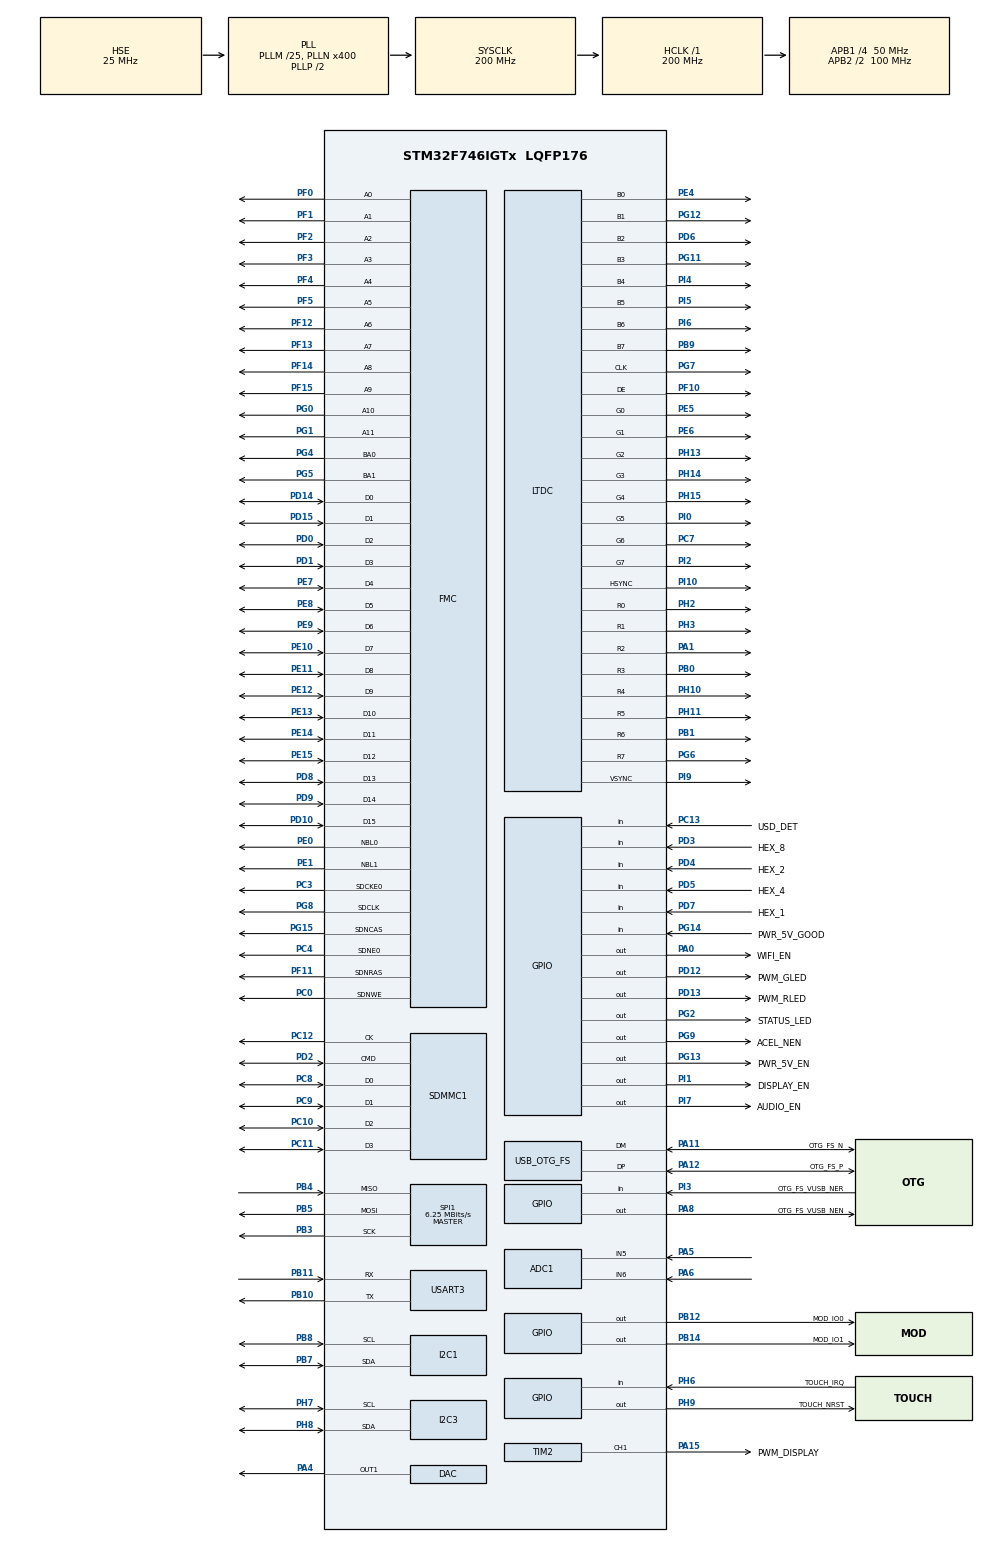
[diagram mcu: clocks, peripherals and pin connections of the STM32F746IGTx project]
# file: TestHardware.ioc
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ADC1.Channel-0\#ChannelRegularConversion=ADC_CHANNEL_5
ADC1.Channel-1\#ChannelRegularConversion=ADC_CHANNEL_6
ADC1.Channel-2\#ChannelRegularConversion=ADC_CHANNEL_TEMPSENSOR
ADC1.ClockPrescaler=ADC_CLOCK_SYNC_PCLK_DIV4
ADC1.ContinuousConvMode=DISABLE
ADC1.DMAContinuousRequests=ENABLE
ADC1.ExternalTrigConv=ADC_EXTERNALTRIGCONV_T1_TRGO
ADC1.NbrOfConversion=3
ADC1.NbrOfConversionFlag=1
ADC1.Rank-0\#ChannelRegularConversion=1
ADC1.Rank-1\#ChannelRegularConversion=2
ADC1.Rank-2\#ChannelRegularConversion=3
ADC1.SamplingTime-0\#ChannelRegularConversion=ADC_SAMPLETIME_28CYCLES
ADC1.SamplingTime-1\#ChannelRegularConversion=ADC_SAMPLETIME_15CYCLES
ADC1.SamplingTime-2\#ChannelRegularConversion=ADC_SAMPLETIME_480CYCLES
ADC1.ScanConvMode=ADC_SCAN_ENABLE
ADC1.master=1
CORTEX_M7.CPU_DCache=Enabled
CORTEX_M7.CPU_ICache=Enabled
DMA2D.ColorMode=DMA2D_OUTPUT_RGB888
Dma.ADC1.0.Direction=DMA_PERIPH_TO_MEMORY
Dma.ADC1.0.FIFOMode=DMA_FIFOMODE_DISABLE
Dma.ADC1.0.Instance=DMA2_Stream0
Dma.ADC1.0.MemDataAlignment=DMA_MDATAALIGN_HALFWORD
Dma.ADC1.0.MemInc=DMA_MINC_ENABLE
Dma.ADC1.0.Mode=DMA_CIRCULAR
Dma.ADC1.0.PeriphDataAlignment=DMA_PDATAALIGN_HALFWORD
Dma.ADC1.0.PeriphInc=DMA_PINC_DISABLE
Dma.ADC1.0.Priority=DMA_PRIORITY_LOW
Dma.Request0=ADC1
Dma.Request1=SDMMC1_RX
Dma.Request2=SDMMC1_TX
Dma.SDMMC1_RX.1.Direction=DMA_PERIPH_TO_MEMORY
Dma.SDMMC1_RX.1.FIFOMode=DMA_FIFOMODE_ENABLE
Dma.SDMMC1_RX.1.FIFOThreshold=DMA_FIFO_THRESHOLD_FULL
Dma.SDMMC1_RX.1.Instance=DMA2_Stream3
Dma.SDMMC1_RX.1.MemBurst=DMA_MBURST_INC4
Dma.SDMMC1_RX.1.MemDataAlignment=DMA_MDATAALIGN_WORD
Dma.SDMMC1_RX.1.MemInc=DMA_MINC_ENABLE
Dma.SDMMC1_RX.1.Mode=DMA_PFCTRL
Dma.SDMMC1_RX.1.PeriphBurst=DMA_PBURST_INC4
Dma.SDMMC1_RX.1.PeriphDataAlignment=DMA_PDATAALIGN_WORD
Dma.SDMMC1_RX.1.PeriphInc=DMA_PINC_DISABLE
Dma.SDMMC1_RX.1.Priority=DMA_PRIORITY_LOW
Dma.SDMMC1_TX.2.Direction=DMA_MEMORY_TO_PERIPH
Dma.SDMMC1_TX.2.FIFOMode=DMA_FIFOMODE_ENABLE
Dma.SDMMC1_TX.2.FIFOThreshold=DMA_FIFO_THRESHOLD_FULL
Dma.SDMMC1_TX.2.Instance=DMA2_Stream6
Dma.SDMMC1_TX.2.MemBurst=DMA_MBURST_INC4
Dma.SDMMC1_TX.2.MemDataAlignment=DMA_MDATAALIGN_WORD
Dma.SDMMC1_TX.2.MemInc=DMA_MINC_ENABLE
Dma.SDMMC1_TX.2.Mode=DMA_PFCTRL
Dma.SDMMC1_TX.2.PeriphBurst=DMA_PBURST_INC4
Dma.SDMMC1_TX.2.PeriphDataAlignment=DMA_PDATAALIGN_WORD
Dma.SDMMC1_TX.2.PeriphInc=DMA_PINC_DISABLE
Dma.SDMMC1_TX.2.Priority=DMA_PRIORITY_LOW
FATFS.BSP.number=1
FATFS.USE_DMA_CODE_SD=1
FATFS._USE_LFN=2
FATFS0.BSP.STBoard=false
FATFS0.BSP.api=Unknown
FATFS0.BSP.i2caddr=0
FATFS0.BSP.instance=PC13
FATFS0.BSP.ip=GPIO
FATFS0.BSP.mode=Input
FATFS0.BSP.name=Detect_SDIO
FATFS0.BSP.solution=PC13
FMC.CASLatency1=FMC_SDRAM_CAS_LATENCY_3
FMC.ExitSelfRefreshDelay1=7
FMC.LoadToActiveDelay1=2
FMC.RCDDelay1=2
FMC.RPDelay1=2
FMC.ReadBurst1=FMC_SDRAM_RBURST_ENABLE
FMC.RowCycleDelay1=7
FMC.SDClockPeriod1=FMC_SDRAM_CLOCK_PERIOD_2
FMC.SelfRefreshTime1=4
FMC.WriteRecoveryTime1=3
I2C1.Timing=0x00C0EAFF
I2C3.I2C_Fall_Time=100
I2C3.I2C_Rise_Time=100
I2C3.Timing=0xC0100F14
LTDC.ActiveH=272
LTDC.ActiveW=480
LTDC.Alpha_L0=255
LTDC.BlendingFactor1_L0=LTDC_BLENDING_FACTOR1_PAxCA
LTDC.BlendingFactor2_L0=LTDC_BLENDING_FACTOR2_PAxCA
LTDC.Blue_L0=0
LTDC.FBStartAdress_L0=0xC0000000
LTDC.Green=0
LTDC.Green_L0=0
LTDC.Green_L1=255
LTDC.HBP=13
LTDC.HFP=32
LTDC.HSync=41
LTDC.ImageHeight_L0=272
LTDC.ImageWidth_L0=480
LTDC.Layers=0
LTDC.PixelFormat_L0=LTDC_PIXEL_FORMAT_RGB888
LTDC.VSync=10
LTDC.WindowX1_L0=480
LTDC.WindowY1_L0=272
Mcu.Family=STM32F7
Mcu.Name=STM32F746IGTx
Mcu.Package=LQFP176
NVIC.DMA2D_IRQn=true\:0\:0\:false\:false\:true\:true\:true
NVIC.DMA2_Stream0_IRQn=true\:0\:0\:true\:false\:true\:false\:true
NVIC.DMA2_Stream3_IRQn=true\:15\:0\:true\:false\:true\:false\:true
NVIC.DMA2_Stream6_IRQn=true\:15\:0\:true\:false\:true\:false\:true
NVIC.LTDC_IRQn=true\:0\:0\:false\:false\:true\:true\:true
NVIC.OTG_FS_IRQn=true\:0\:0\:false\:false\:true\:true\:true
NVIC.PriorityGroup=NVIC_PRIORITYGROUP_4
NVIC.SDMMC1_IRQn=true\:14\:0\:true\:false\:true\:true\:true
NVIC.TIM1_UP_TIM10_IRQn=true\:0\:0\:false\:false\:true\:true\:true
NVIC.TIM3_IRQn=true\:0\:0\:false\:false\:true\:true\:true
NVIC.USART3_IRQn=true\:0\:0\:false\:false\:true\:true\:true
PA0/WKUP.GPIO_Label=WIFI_EN
PA0/WKUP.Signal=GPIO_Output
PA1.GPIO_Speed=GPIO_SPEED_FREQ_VERY_HIGH
PA1.Mode=RGB888
PA1.Signal=LTDC_R2
PA11.GPIO_Label=OTG_FS_N
PA11.Mode=Device_Only
PA11.Signal=USB_OTG_FS_DM
PA12.GPIO_Label=OTG_FS_P
PA12.Mode=Device_Only
PA12.Signal=USB_OTG_FS_DP
PA13.Mode=Serial_Wire
PA13.Signal=SYS_JTMS-SWDIO
PA14.Mode=Serial_Wire
PA14.Signal=SYS_JTCK-SWCLK
PA15.GPIO_Label=PWM_DISPLAY
PA15.Signal=S_TIM2_CH1_ETR
PA4.Signal=COMP_DAC1_group
PA5.Signal=ADCx_IN5
PA6.Signal=ADCx_IN6
PA8.GPIO_Label=OTG_FS_VUSB_NEN
PA8.Signal=GPIO_Output
PB0.GPIO_Speed=GPIO_SPEED_FREQ_VERY_HIGH
PB0.Mode=RGB888
PB0.Signal=LTDC_R3
PB1.GPIO_Speed=GPIO_SPEED_FREQ_VERY_HIGH
PB1.Mode=RGB888
PB1.Signal=LTDC_R6
PB10.Mode=Asynchronous
PB10.Signal=USART3_TX
PB11.Mode=Asynchronous
PB11.Signal=USART3_RX
PB12.GPIO_Label=MOD_IO0
PB12.Signal=GPIO_Output
PB14.GPIO_Label=MOD_IO1
PB14.Signal=GPIO_Output
PB3.Mode=Full_Duplex_Master
PB3.Signal=SPI1_SCK
PB4.Mode=Full_Duplex_Master
PB4.Signal=SPI1_MISO
PB5.Mode=Full_Duplex_Master
PB5.Signal=SPI1_MOSI
PB7.Mode=I2C
PB7.Signal=I2C1_SDA
PB8.Mode=I2C
PB8.Signal=I2C1_SCL
PB9.GPIO_Speed=GPIO_SPEED_FREQ_VERY_HIGH
PB9.Mode=RGB888
PB9.Signal=LTDC_B7
PC0.Signal=FMC_SDNWE
PC10.Mode=SD_4_bits_Wide_bus
PC10.Signal=SDMMC1_D2
PC11.Mode=SD_4_bits_Wide_bus
PC11.Signal=SDMMC1_D3
PC12.Mode=SD_4_bits_Wide_bus
PC12.Signal=SDMMC1_CK
PC13.GPIO_Label=USD_DET
PC13.Signal=GPIO_Input
PC14/OSC32_IN.Mode=LSE-External-Oscillator
PC14/OSC32_IN.Signal=RCC_OSC32_IN
PC15/OSC32_OUT.Mode=LSE-External-Oscillator
PC15/OSC32_OUT.Signal=RCC_OSC32_OUT
PC3.Mode=SdramChipSelect1_1
PC3.Signal=FMC_SDCKE0
PC4.Mode=SdramChipSelect1_1
PC4.Signal=FMC_SDNE0
PC7.GPIO_Speed=GPIO_SPEED_FREQ_VERY_HIGH
PC7.Mode=RGB888
PC7.Signal=LTDC_G6
PC8.Mode=SD_4_bits_Wide_bus
PC8.Signal=SDMMC1_D0
PC9.Mode=SD_4_bits_Wide_bus
PC9.Signal=SDMMC1_D1
PD0.Signal=FMC_D2_DA2
PD1.Signal=FMC_D3_DA3
PD10.Signal=FMC_D15_DA15
PD12.GPIO_Label=PWM_GLED
PD12.Signal=GPIO_Output
PD13.GPIO_Label=PWM_RLED
PD13.Signal=GPIO_Output
PD14.Signal=FMC_D0_DA0
PD15.Signal=FMC_D1_DA1
PD2.Mode=SD_4_bits_Wide_bus
PD2.Signal=SDMMC1_CMD
PD3.GPIO_Label=HEX_8
PD3.Signal=GPIO_Input
PD4.GPIO_Label=HEX_2
PD4.Signal=GPIO_Input
PD5.GPIO_Label=HEX_4
PD5.Signal=GPIO_Input
PD6.GPIO_Speed=GPIO_SPEED_FREQ_VERY_HIGH
PD6.Mode=RGB888
PD6.Signal=LTDC_B2
PD7.GPIO_Label=HEX_1
PD7.Signal=GPIO_Input
PD8.Signal=FMC_D13_DA13
PD9.Signal=FMC_D14_DA14
PE0.Signal=FMC_NBL0
PE1.Signal=FMC_NBL1
PE10.Signal=FMC_D7_DA7
PE11.Signal=FMC_D8_DA8
PE12.Signal=FMC_D9_DA9
PE13.Signal=FMC_D10_DA10
PE14.Signal=FMC_D11_DA11
PE15.Signal=FMC_D12_DA12
PE4.GPIO_Speed=GPIO_SPEED_FREQ_VERY_HIGH
PE4.Mode=RGB888
PE4.Signal=LTDC_B0
PE5.GPIO_Speed=GPIO_SPEED_FREQ_VERY_HIGH
PE5.Mode=RGB888
PE5.Signal=LTDC_G0
PE6.GPIO_Speed=GPIO_SPEED_FREQ_VERY_HIGH
PE6.Mode=RGB888
PE6.Signal=LTDC_G1
PE7.Signal=FMC_D4_DA4
PE8.Signal=FMC_D5_DA5
PE9.Signal=FMC_D6_DA6
PF0.Signal=FMC_A0
PF1.Signal=FMC_A1
PF10.GPIO_Speed=GPIO_SPEED_FREQ_VERY_HIGH
PF10.Mode=RGB888
PF10.Signal=LTDC_DE
PF11.Signal=FMC_SDNRAS
PF12.Signal=FMC_A6
PF13.Signal=FMC_A7
PF14.Signal=FMC_A8
PF15.Signal=FMC_A9
PF2.Signal=FMC_A2
PF3.Signal=FMC_A3
PF4.Signal=FMC_A4
PF5.Signal=FMC_A5
PG0.Signal=FMC_A10
PG1.Signal=FMC_A11
PG11.GPIO_Speed=GPIO_SPEED_FREQ_VERY_HIGH
PG11.Mode=RGB888
PG11.Signal=LTDC_B3
PG12.GPIO_Speed=GPIO_SPEED_FREQ_VERY_HIGH
PG12.Mode=RGB888
PG12.Signal=LTDC_B1
PG13.GPIO_Label=PWR_5V_EN
PG13.Signal=GPIO_Output
PG14.GPIO_Label=PWR_5V_GOOD
PG14.Signal=GPIO_Input
PG15.Signal=FMC_SDNCAS
PG2.GPIO_Label=STATUS_LED
PG2.Signal=GPIO_Output
PG4.Signal=FMC_A14_BA0
PG5.Signal=FMC_A15_BA1
PG6.GPIO_Speed=GPIO_SPEED_FREQ_VERY_HIGH
PG6.Mode=RGB888
PG6.Signal=LTDC_R7
PG7.GPIO_Speed=GPIO_SPEED_FREQ_VERY_HIGH
PG7.Mode=RGB888
PG7.Signal=LTDC_CLK
PG8.Signal=FMC_SDCLK
PG9.GPIO_Label=ACEL_NEN
PG9.Signal=GPIO_Output
PH0/OSC_IN.Mode=HSE-External-Oscillator
PH0/OSC_IN.Signal=RCC_OSC_IN
PH1/OSC_OUT.Mode=HSE-External-Oscillator
PH1/OSC_OUT.Signal=RCC_OSC_OUT
PH10.GPIO_Speed=GPIO_SPEED_FREQ_VERY_HIGH
PH10.Mode=RGB888
PH10.Signal=LTDC_R4
PH11.GPIO_Speed=GPIO_SPEED_FREQ_VERY_HIGH
PH11.Mode=RGB888
PH11.Signal=LTDC_R5
PH13.GPIO_Speed=GPIO_SPEED_FREQ_VERY_HIGH
PH13.Mode=RGB888
PH13.Signal=LTDC_G2
PH14.GPIO_Speed=GPIO_SPEED_FREQ_VERY_HIGH
PH14.Mode=RGB888
PH14.Signal=LTDC_G3
PH15.GPIO_Speed=GPIO_SPEED_FREQ_VERY_HIGH
PH15.Mode=RGB888
PH15.Signal=LTDC_G4
PH2.GPIO_Speed=GPIO_SPEED_FREQ_VERY_HIGH
PH2.Mode=RGB888
PH2.Signal=LTDC_R0
PH3.GPIO_Speed=GPIO_SPEED_FREQ_VERY_HIGH
PH3.Mode=RGB888
PH3.Signal=LTDC_R1
PH6.GPIO_Label=TOUCH_IRQ
PH6.Signal=GPIO_Input
PH7.Mode=I2C
PH7.Signal=I2C3_SCL
PH8.Mode=I2C
PH8.Signal=I2C3_SDA
PH9.GPIO_Label=TOUCH_NRST
PH9.Signal=GPIO_Output
PI0.GPIO_Speed=GPIO_SPEED_FREQ_VERY_HIGH
PI0.Mode=RGB888
PI0.Signal=LTDC_G5
PI1.GPIO_Label=DISPLAY_EN
PI1.Signal=GPIO_Output
PI10.GPIO_Speed=GPIO_SPEED_FREQ_VERY_HIGH
PI10.Mode=RGB888
PI10.Signal=LTDC_HSYNC
PI2.GPIO_Speed=GPIO_SPEED_FREQ_VERY_HIGH
PI2.Mode=RGB888
PI2.Signal=LTDC_G7
PI3.GPIO_Label=OTG_FS_VUSB_NER
PI3.Signal=GPIO_Input
PI4.GPIO_Speed=GPIO_SPEED_FREQ_VERY_HIGH
PI4.Mode=RGB888
PI4.Signal=LTDC_B4
PI5.GPIO_Speed=GPIO_SPEED_FREQ_VERY_HIGH
PI5.Mode=RGB888
PI5.Signal=LTDC_B5
PI6.GPIO_Speed=GPIO_SPEED_FREQ_VERY_HIGH
PI6.Mode=RGB888
PI6.Signal=LTDC_B6
PI7.GPIO_Label=AUDIO_EN
PI7.Signal=GPIO_Output
PI9.GPIO_Speed=GPIO_SPEED_FREQ_VERY_HIGH
PI9.Mode=RGB888
PI9.Signal=LTDC_VSYNC
ProjectManager.HeapSize=0x1400
ProjectManager.StackSize=0x1000
ProjectManager.TargetToolchain=TrueSTUDIO
RCC.AHBFreq_Value=200000000
RCC.APB1CLKDivider=RCC_HCLK_DIV4
RCC.APB1Freq_Value=50000000
RCC.APB1TimFreq_Value=100000000
RCC.APB2CLKDivider=RCC_HCLK_DIV2
RCC.APB2Freq_Value=100000000
RCC.APB2TimFreq_Value=200000000
RCC.CortexFreq_Value=200000000
RCC.HCLKFreq_Value=200000000
RCC.HSE_VALUE=25000000
RCC.HSI_VALUE=16000000
RCC.PLL48CLockSelection=RCC_CLK48SOURCE_PLLSAIP
RCC.PLLM=25
RCC.PLLN=400
RCC.PLLQ=8
RCC.PLLSAIN=384
RCC.PLLSAIP=RCC_PLLSAIP_DIV8
RCC.PLLSAIR=5
RCC.PLLSAIRDiv=RCC_PLLSAIDIVR_8
RCC.SDMMCClockSelection=RCC_SDMMC1CLKSOURCE_CLK48
RCC.SYSCLKFreq_VALUE=200000000
RCC.SYSCLKSource=RCC_SYSCLKSOURCE_PLLCLK
RCC.USBFreq_Value=48000000
RCC.VCOOutputFreq_Value=400000000
SH.ADCx_IN5.0=ADC1_IN5,IN5
SH.ADCx_IN6.0=ADC1_IN6,IN6
SH.COMP_DAC1_group.0=DAC_OUT1,DAC_OUT1
SH.FMC_A0.0=FMC_A0,12b-sda1
SH.FMC_A1.0=FMC_A1,12b-sda1
SH.FMC_A10.0=FMC_A10,12b-sda1
SH.FMC_A11.0=FMC_A11,12b-sda1
SH.FMC_A14_BA0.0=FMC_BA0,FourSdramBanks1
SH.FMC_A15_BA1.0=FMC_BA1,FourSdramBanks1
SH.FMC_A2.0=FMC_A2,12b-sda1
SH.FMC_A3.0=FMC_A3,12b-sda1
SH.FMC_A4.0=FMC_A4,12b-sda1
SH.FMC_A5.0=FMC_A5,12b-sda1
SH.FMC_A6.0=FMC_A6,12b-sda1
SH.FMC_A7.0=FMC_A7,12b-sda1
SH.FMC_A8.0=FMC_A8,12b-sda1
SH.FMC_A9.0=FMC_A9,12b-sda1
SH.FMC_D0_DA0.0=FMC_D0,sd-16b-d1
SH.FMC_D10_DA10.0=FMC_D10,sd-16b-d1
SH.FMC_D11_DA11.0=FMC_D11,sd-16b-d1
SH.FMC_D12_DA12.0=FMC_D12,sd-16b-d1
SH.FMC_D13_DA13.0=FMC_D13,sd-16b-d1
SH.FMC_D14_DA14.0=FMC_D14,sd-16b-d1
SH.FMC_D15_DA15.0=FMC_D15,sd-16b-d1
SH.FMC_D1_DA1.0=FMC_D1,sd-16b-d1
SH.FMC_D2_DA2.0=FMC_D2,sd-16b-d1
SH.FMC_D3_DA3.0=FMC_D3,sd-16b-d1
SH.FMC_D4_DA4.0=FMC_D4,sd-16b-d1
SH.FMC_D5_DA5.0=FMC_D5,sd-16b-d1
SH.FMC_D6_DA6.0=FMC_D6,sd-16b-d1
SH.FMC_D7_DA7.0=FMC_D7,sd-16b-d1
SH.FMC_D8_DA8.0=FMC_D8,sd-16b-d1
SH.FMC_D9_DA9.0=FMC_D9,sd-16b-d1
SH.FMC_NBL0.0=FMC_NBL0,Sd2ByteEnable1
SH.FMC_NBL1.0=FMC_NBL1,Sd2ByteEnable1
SH.FMC_SDCLK.0=FMC_SDCLK,12b-sda1
SH.FMC_SDNCAS.0=FMC_SDNCAS,12b-sda1
SH.FMC_SDNRAS.0=FMC_SDNRAS,12b-sda1
SH.FMC_SDNWE.0=FMC_SDNWE,12b-sda1
SH.S_TIM2_CH1_ETR.0=TIM2_CH1,PWM Generation1 CH1
SPI1.BaudRatePrescaler=SPI_BAUDRATEPRESCALER_16
SPI1.CalculateBaudRate=6.25 MBits/s
SPI1.DataSize=SPI_DATASIZE_8BIT
SPI1.Direction=SPI_DIRECTION_2LINES
SPI1.Mode=SPI_MODE_MASTER
SPI1.VirtualType=VM_MASTER
TIM1.AutoReloadPreload=TIM_AUTORELOAD_PRELOAD_ENABLE
TIM1.Channel-Output\ Compare1\ No\ Output=TIM_CHANNEL_1
TIM1.Period=100-1
TIM1.Prescaler=1000-1
TIM1.TIM_MasterOutputTrigger=TIM_TRGO_UPDATE
TIM2.Channel-PWM\ Generation1\ CH1=TIM_CHANNEL_1
TIM2.Period=100-1
TIM2.Prescaler=100-1
TIM2.Pulse-PWM\ Generation1\ CH1=50-1
TIM3.Period=100-1
TIM3.Prescaler=10-1
USART3.VirtualMode-Asynchronous=VM_ASYNC
USB_DEVICE.APP_RX_DATA_SIZE-CDC_FS=2048
USB_DEVICE.APP_TX_DATA_SIZE-CDC_FS=2048
USB_DEVICE.CLASS_NAME_FS=CDC
USB_DEVICE.VirtualMode-CDC_FS=Cdc
USB_DEVICE.VirtualModeFS=Cdc_FS
USB_OTG_FS.VirtualMode=Device_Only
VP_ADC1_TempSens_Input.Mode=IN-TempSens
VP_CRC_VS_CRC.Mode=CRC_Activate
VP_DMA2D_VS_DMA2D.Mode=DMA2D_Activate
VP_FATFS_VS_SDIO.Mode=SDIO
VP_TIM1_VS_no_output1.Mode=Output Compare1 No Output
VP_TIM2_VS_ClockSourceINT.Mode=Internal
VP_TIM3_VS_ClockSourceINT.Mode=Internal
VP_USB_DEVICE_VS_USB_DEVICE_CDC_FS.Mode=CDC_FS
board=custom

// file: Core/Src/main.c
/* USER CODE BEGIN Header */
/**
  ******************************************************************************
  * @file           : main.c
  * @brief          : Main program body
  ******************************************************************************
  * @attention
  *
  * <h2><center>&copy; Copyright (c) 2021 STMicroelectronics.
  * All rights reserved.</center></h2>
  *
  * This software component is licensed by ST under Ultimate Liberty license
  * SLA0044, the "License"; You may not use this file except in compliance with
  * the License. You may obtain a copy of the License at:
  *                             www.st.com/SLA0044
  *
  ******************************************************************************
  */
/* USER CODE END Header */
#include "main.h"
#include "adc.h"
#include "crc.h"
#include "dac.h"
#include "dma.h"
#include "dma2d.h"
#include "fatfs.h"
#include "i2c.h"
#include "ltdc.h"
#include "sdmmc.h"
#include "spi.h"
#include "tim.h"
#include "usart.h"
#include "usb_device.h"
#include "gpio.h"
#include "fmc.h"

/* USER CODE BEGIN Includes */
#include "MainSupport.h"
#include "UartSupport.h"
/* USER CODE END Includes */

void SystemClock_Config(void);

int main(void)
{

  /* Enable I-Cache---------------------------------------------------------*/
  SCB_EnableICache();

  /* Enable D-Cache---------------------------------------------------------*/
  SCB_EnableDCache();

  /* MCU Configuration--------------------------------------------------------*/

  /* Reset of all peripherals, Initializes the Flash interface and the Systick. */
  HAL_Init();

  /* Configure the system clock */
  SystemClock_Config();

  /* Initialize all configured peripherals */
  MX_GPIO_Init();
  MX_DMA_Init();
  MX_USART3_UART_Init();
  MX_ADC1_Init();
  MX_TIM1_Init();
  MX_TIM2_Init();
  MX_SDMMC1_SD_Init();
  MX_FATFS_Init();
  MX_FMC_Init();
  MX_USB_DEVICE_Init();
  MX_LTDC_Init();
  MX_DMA2D_Init();
  MX_CRC_Init();
  MX_I2C1_Init();
  MX_SPI1_Init();
  MX_DAC_Init();
  MX_I2C3_Init();
  MX_TIM3_Init();
  /* USER CODE BEGIN 2 */
  main_Init();
  /* USER CODE END 2 */

  /* Infinite loop */
  while (1)
  {
	  main_WhileLoop();
  }
}

void SystemClock_Config(void)
{
  RCC_OscInitTypeDef RCC_OscInitStruct = {0};
  RCC_ClkInitTypeDef RCC_ClkInitStruct = {0};
  RCC_PeriphCLKInitTypeDef PeriphClkInitStruct = {0};

  /** Configure LSE Drive Capability
  */
  HAL_PWR_EnableBkUpAccess();
  /** Configure the main internal regulator output voltage
  */
  __HAL_RCC_PWR_CLK_ENABLE();
  __HAL_PWR_VOLTAGESCALING_CONFIG(PWR_REGULATOR_VOLTAGE_SCALE1);
  /** Initializes the RCC Oscillators according to the specified parameters
  * in the RCC_OscInitTypeDef structure.
  */
  RCC_OscInitStruct.OscillatorType = RCC_OSCILLATORTYPE_HSE;
  RCC_OscInitStruct.HSEState = RCC_HSE_ON;
  RCC_OscInitStruct.PLL.PLLState = RCC_PLL_ON;
  RCC_OscInitStruct.PLL.PLLSource = RCC_PLLSOURCE_HSE;
  RCC_OscInitStruct.PLL.PLLM = 25;
  RCC_OscInitStruct.PLL.PLLN = 400;
  RCC_OscInitStruct.PLL.PLLP = RCC_PLLP_DIV2;
  RCC_OscInitStruct.PLL.PLLQ = 8;
  if (HAL_RCC_OscConfig(&RCC_OscInitStruct) != HAL_OK)
  {
    Error_Handler();
  }
  /** Activate the Over-Drive mode
  */
  if (HAL_PWREx_EnableOverDrive() != HAL_OK)
  {
    Error_Handler();
  }
  /** Initializes the CPU, AHB and APB buses clocks
  */
  RCC_ClkInitStruct.ClockType = RCC_CLOCKTYPE_HCLK|RCC_CLOCKTYPE_SYSCLK
                              |RCC_CLOCKTYPE_PCLK1|RCC_CLOCKTYPE_PCLK2;
  RCC_ClkInitStruct.SYSCLKSource = RCC_SYSCLKSOURCE_PLLCLK;
  RCC_ClkInitStruct.AHBCLKDivider = RCC_SYSCLK_DIV1;
  RCC_ClkInitStruct.APB1CLKDivider = RCC_HCLK_DIV4;
  RCC_ClkInitStruct.APB2CLKDivider = RCC_HCLK_DIV2;

  if (HAL_RCC_ClockConfig(&RCC_ClkInitStruct, FLASH_LATENCY_6) != HAL_OK)
  {
    Error_Handler();
  }
  PeriphClkInitStruct.PeriphClockSelection = RCC_PERIPHCLK_LTDC|RCC_PERIPHCLK_USART3
                              |RCC_PERIPHCLK_I2C1|RCC_PERIPHCLK_I2C3
                              |RCC_PERIPHCLK_SDMMC1|RCC_PERIPHCLK_CLK48;
  PeriphClkInitStruct.PLLSAI.PLLSAIN = 384;
  PeriphClkInitStruct.PLLSAI.PLLSAIR = 5;
  PeriphClkInitStruct.PLLSAI.PLLSAIQ = 2;
  PeriphClkInitStruct.PLLSAI.PLLSAIP = RCC_PLLSAIP_DIV8;
  PeriphClkInitStruct.PLLSAIDivQ = 1;
  PeriphClkInitStruct.PLLSAIDivR = RCC_PLLSAIDIVR_8;
  PeriphClkInitStruct.Usart3ClockSelection = RCC_USART3CLKSOURCE_PCLK1;
  PeriphClkInitStruct.I2c1ClockSelection = RCC_I2C1CLKSOURCE_PCLK1;
  PeriphClkInitStruct.I2c3ClockSelection = RCC_I2C3CLKSOURCE_PCLK1;
  PeriphClkInitStruct.Clk48ClockSelection = RCC_CLK48SOURCE_PLLSAIP;
  PeriphClkInitStruct.Sdmmc1ClockSelection = RCC_SDMMC1CLKSOURCE_CLK48;
  if (HAL_RCCEx_PeriphCLKConfig(&PeriphClkInitStruct) != HAL_OK)
  {
    Error_Handler();
  }
}

void Error_Handler(void)
{
  /* USER CODE BEGIN Error_Handler_Debug */
	printErrorHandler();
  /* User can add his own implementation to report the HAL error return state */
  __disable_irq();
  while (1)
  {
  }
  /* USER CODE END Error_Handler_Debug */
}

/************************ (C) COPYRIGHT STMicroelectronics *****END OF FILE****/
